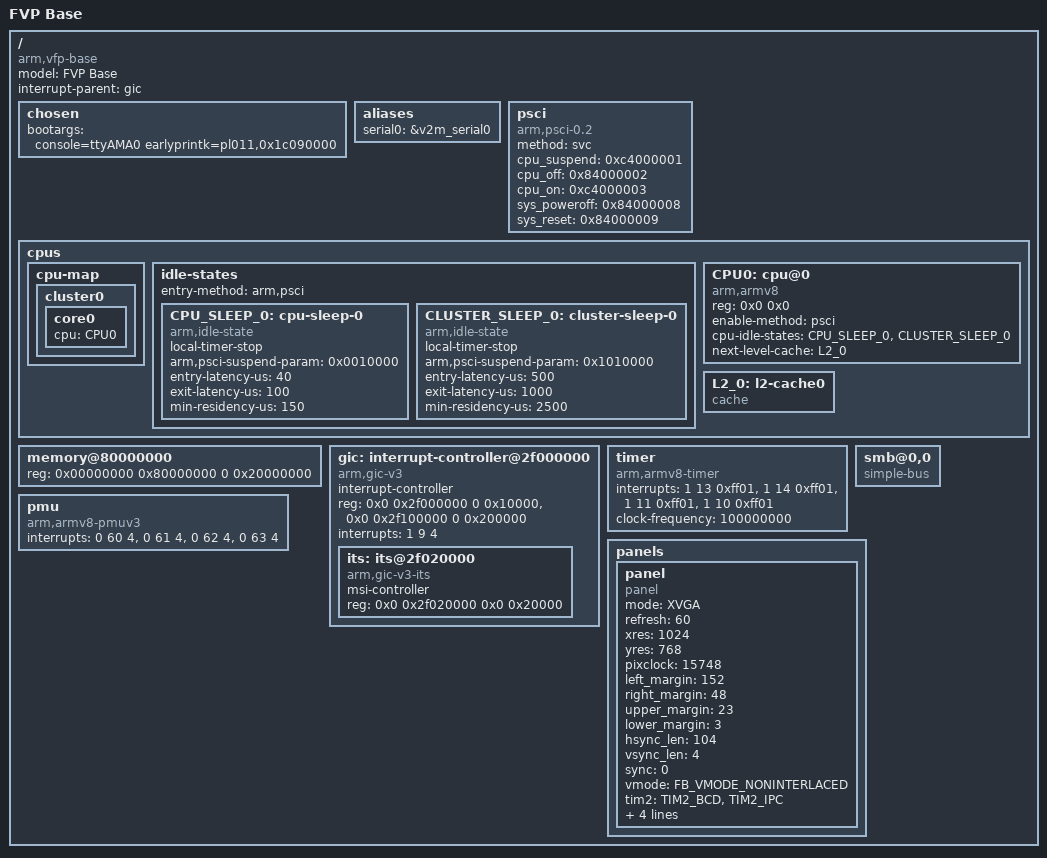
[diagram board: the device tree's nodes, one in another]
/*
 * Copyright (c) 2017-2018, ARM Limited and Contributors. All rights reserved.
 *
 * SPDX-License-Identifier: BSD-3-Clause
 */

/memreserve/ 0x80000000 0x00010000;

/ {
};

/ {
	model = "FVP Base";
	compatible = "arm,vfp-base", "arm,vexpress";
	interrupt-parent = <&gic>;
	#address-cells = <2>;
	#size-cells = <2>;

	chosen { 
		bootargs = "console=ttyAMA0 earlyprintk=pl011,0x1c090000";
	};

	aliases {
		serial0 = &v2m_serial0;
	};

	psci {
		compatible = "arm,psci-0.2", "arm,psci";
		method = "svc";
		cpu_suspend = <0xc4000001>;
		cpu_off = <0x84000002>;
		cpu_on = <0xc4000003>;
		sys_poweroff = <0x84000008>;
		sys_reset = <0x84000009>;
	};

	cpus {
		#address-cells = <2>;
		#size-cells = <0>;

		cpu-map {
			cluster0 {
				core0 {
					cpu = <&CPU0>;
				};
			};
		};

		idle-states {
			entry-method = "arm,psci";

			CPU_SLEEP_0: cpu-sleep-0 {
				compatible = "arm,idle-state";
				local-timer-stop;
				arm,psci-suspend-param = <0x0010000>;
				entry-latency-us = <40>;
				exit-latency-us = <100>;
				min-residency-us = <150>;
			};

			CLUSTER_SLEEP_0: cluster-sleep-0 {
				compatible = "arm,idle-state";
				local-timer-stop;
				arm,psci-suspend-param = <0x1010000>;
				entry-latency-us = <500>;
				exit-latency-us = <1000>;
				min-residency-us = <2500>;
			};
		};

		CPU0:cpu@0 {
			device_type = "cpu";
			compatible = "arm,armv8";
			reg = <0x0 0x0>;
			enable-method = "psci";
			cpu-idle-states = <&CPU_SLEEP_0 &CLUSTER_SLEEP_0>;
			next-level-cache = <&L2_0>;
		};

		L2_0: l2-cache0 {
			compatible = "cache";
		};
	};

	memory@80000000 {
		device_type = "memory";
		reg = <0x00000000 0x80000000 0 0x20000000>;
	};

	gic: interrupt-controller@2f000000 {
		compatible = "arm,gic-v3";
		#interrupt-cells = <3>;
		#address-cells = <2>;
		#size-cells = <2>;
		ranges;
		interrupt-controller;

		reg = <0x0 0x2f000000 0 0x10000>,
		      <0x0 0x2f100000 0 0x200000>;
		interrupts = <1 9 4>;

		its: its@2f020000 {
			compatible = "arm,gic-v3-its";
			msi-controller;
			reg = <0x0 0x2f020000 0x0 0x20000>;
		};
	};

	timer {
		compatible = "arm,armv8-timer";
		interrupts = <1 13 0xff01>,
			     <1 14 0xff01>,
			     <1 11 0xff01>,
			     <1 10 0xff01>;
		clock-frequency = <100000000>;
	};

	pmu {
		compatible = "arm,armv8-pmuv3";
		interrupts = <0 60 4>,
			     <0 61 4>,
			     <0 62 4>,
			     <0 63 4>;
	};

	smb@0,0 {
		compatible = "simple-bus";

		#address-cells = <2>;
		#size-cells = <1>;

		ranges = <0 0 0 0x08000000 0x04000000>,
			 <1 0 0 0x14000000 0x04000000>,
			 <2 0 0 0x18000000 0x04000000>,
			 <3 0 0 0x1c000000 0x04000000>,
			 <4 0 0 0x0c000000 0x04000000>,
			 <5 0 0 0x10000000 0x04000000>;

		/include/ "rtsm_ve-motherboard-simple.dtsi"
	};

	panels {
		panel {
			compatible	= "panel";
			mode		= "XVGA";
			refresh		= <60>;
			xres		= <1024>;
			yres		= <768>;
			pixclock	= <15748>;
			left_margin	= <152>;
			right_margin	= <48>;
			upper_margin	= <23>;
			lower_margin	= <3>;
			hsync_len	= <104>;
			vsync_len	= <4>;
			sync		= <0>;
			vmode		= "FB_VMODE_NONINTERLACED";
			tim2		= "TIM2_BCD", "TIM2_IPC";
			cntl		= "CNTL_LCDTFT", "CNTL_BGR", "CNTL_LCDVCOMP(1)";
			caps		= "CLCD_CAP_5551", "CLCD_CAP_565", "CLCD_CAP_888";
			bpp		= <16>;
		};
	};

};
